VERSION ""

NS_ :

	智
	SG_MUL_VAL_

BS_:

BU_:

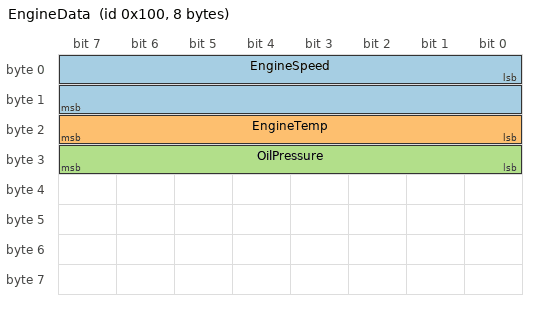
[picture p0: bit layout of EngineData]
BO_ 256 EngineData: 8 Vector__XXX
 SG_ EngineSpeed : 0|16@1+ (1,0) [0|8000] "rpm" Vector__XXX
 SG_ EngineTemp : 16|8@1+ (1,-40) [-40|215] "degC" Vector__XXX
 SG_ OilPressure : 24|8@1+ (0.1,0) [0|25] "bar" Vector__XXX

BO_ 512 TransmissionData: 4 Vector__XXX
 SG_ GearPos : 0|4@1+ (1,0) [0|15] "" Vector__XXX
 SG_ VehicleSpeed : 4|12@1+ (0.1,0) [0|400] "km/h" Vector__XXX

BO_ 768 AmbientData: 2 Vector__XXX
 SG_ OutsideTemp : 0|8@1+ (1,-40) [-40|100] "degC" Vector__XXX
 SG_ Humidity : 8|8@1+ (0.5,0) [0|100] "%" Vector__XXX

CM_ BO_ 256 "Engine status information";
CM_ SG_ 256 EngineSpeed "Current engine rotations per minute";
CM_ BO_ 512 "Transmission status and vehicle speed";
CM_ BO_ 768 "Environment sensor data";

VAL_ 512 GearPos 0 "Neutral" 1 "First" 2 "Second" 3 "Third" 4 "Fourth" 5 "Fifth" 6 "Sixth" 7 "Reverse" 15 "Error" ;
